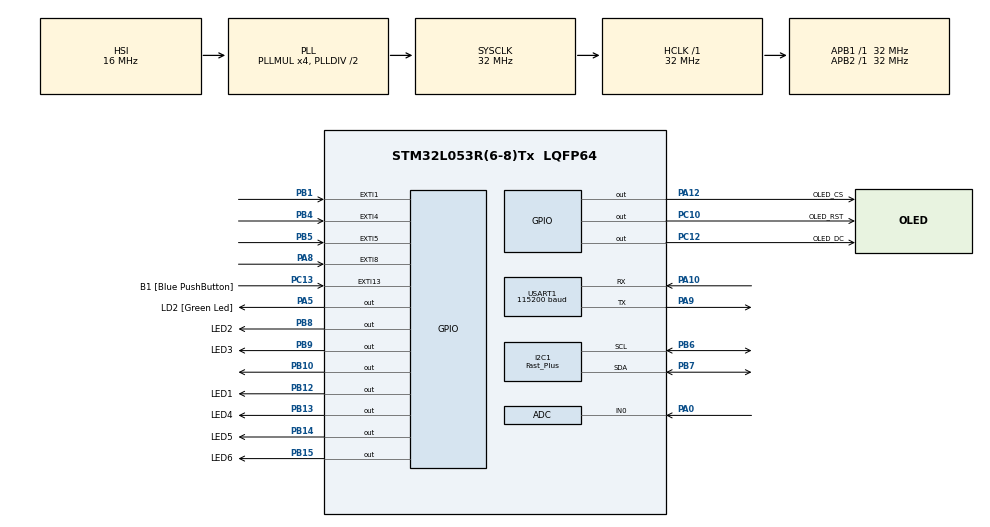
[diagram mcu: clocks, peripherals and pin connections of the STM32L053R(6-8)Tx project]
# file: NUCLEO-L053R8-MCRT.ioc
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ADC.ContinuousConvMode=DISABLE
ADC.DMAContinuousRequests=DISABLE
I2C1.I2C_Speed_Mode=I2C_Fast_Plus
I2C1.Timing=0x00100413
Mcu.Family=STM32L0
Mcu.Name=STM32L053R(6-8)Tx
Mcu.Package=LQFP64
NVIC.EXTI0_1_IRQn=true\:0\:0\:false\:false\:true\:true\:true
NVIC.EXTI4_15_IRQn=true\:0\:0\:false\:false\:true\:true\:true
NVIC.TIM2_IRQn=true\:0\:0\:false\:false\:true\:true\:true
NVIC.TIM6_DAC_IRQn=true\:0\:0\:false\:false\:true\:true\:true
NVIC.USART1_IRQn=true\:0\:0\:false\:false\:true\:true\:true
PA0.Mode=IN0
PA0.Signal=ADC_IN0
PA10.Mode=Asynchronous
PA10.Signal=USART1_RX
PA12.GPIO_Label=OLED_CS
PA12.Signal=GPIO_Output
PA13.GPIO_Label=TMS
PA13.Mode=Serial_Wire
PA13.Signal=SYS_SWDIO
PA14.GPIO_Label=TCK
PA14.Mode=Serial_Wire
PA14.Signal=SYS_SWCLK
PA2.GPIO_Label=USART_TX
PA2.Signal=USART2_TX
PA3.GPIO_Label=USART_RX
PA3.Signal=USART2_RX
PA5.GPIO_Label=LD2 [Green Led]
PA5.Signal=GPIO_Output
PA8.GPIO_ModeDefaultEXTI=GPIO_MODE_IT_RISING_FALLING
PA8.Signal=GPXTI8
PA9.Mode=Asynchronous
PA9.Signal=USART1_TX
PB1.Signal=GPXTI1
PB10.Signal=GPIO_Output
PB12.GPIO_Label=LED1
PB12.Signal=GPIO_Output
PB13.GPIO_Label=LED4
PB13.Signal=GPIO_Output
PB14.GPIO_Label=LED5
PB14.Signal=GPIO_Output
PB15.GPIO_Label=LED6
PB15.Signal=GPIO_Output
PB4.Signal=GPXTI4
PB5.Signal=GPXTI5
PB6.Mode=I2C
PB6.Signal=I2C1_SCL
PB7.Mode=I2C
PB7.Signal=I2C1_SDA
PB8.GPIO_Label=LED2
PB8.Signal=GPIO_Output
PB9.GPIO_Label=LED3
PB9.Signal=GPIO_Output
PC10.GPIO_Label=OLED_RST
PC10.Signal=GPIO_Output
PC12.GPIO_Label=OLED_DC
PC12.Signal=GPIO_Output
PC13.GPIO_Label=B1 [Blue PushButton]
PC13.GPIO_ModeDefaultEXTI=GPIO_MODE_IT_FALLING
PC13.Signal=GPXTI13
PC14-OSC32_IN.Mode=LSE-External-Oscillator
PC14-OSC32_IN.Signal=RCC_OSC32_IN
PC15-OSC32_OUT.Mode=LSE-External-Oscillator
PC15-OSC32_OUT.Signal=RCC_OSC32_OUT
PH0-OSC_IN.Mode=HSE-External-Clock-Source
PH0-OSC_IN.Signal=RCC_OSC_IN
PH1-OSC_OUT.Signal=RCC_OSC_OUT
ProjectManager.HeapSize=0x200
ProjectManager.StackSize=0x400
ProjectManager.TargetToolchain=STM32CubeIDE
RCC.AHBFreq_Value=32000000
RCC.APB1Freq_Value=32000000
RCC.APB1TimFreq_Value=32000000
RCC.APB2Freq_Value=32000000
RCC.APB2TimFreq_Value=32000000
RCC.HCLKFreq_Value=32000000
RCC.HSE_VALUE=8000000
RCC.HSI16_VALUE=16000000
RCC.HSI48_VALUE=48000000
RCC.HSI_VALUE=16000000
RCC.MSI_VALUE=2097000
RCC.PLLMUL=RCC_PLLMUL_4
RCC.SYSCLKFreq_VALUE=32000000
RCC.SYSCLKSource=RCC_SYSCLKSOURCE_PLLCLK
RCC.VCOOutputFreq_Value=64000000
TIM2.Period=32000
TIM6.Period=10000
USART1.BaudRate=115200
USART1.VirtualMode-Asynchronous=VM_ASYNC
VP_TIM2_VS_ClockSourceINT.Mode=Internal
VP_TIM6_VS_ClockSourceINT.Mode=Enable_Timer
board=NUCLEO-L053R8

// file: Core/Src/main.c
/* USER CODE BEGIN Header */
/**
  ******************************************************************************
  * @file           : main.c
  * @brief          : Main program body
  ******************************************************************************
  * @attention
  *
  * <h2><center>&copy; Copyright (c) 2021 STMicroelectronics.
  * All rights reserved.</center></h2>
  *
  * This software component is licensed by ST under BSD 3-Clause license,
  * the "License"; You may not use this file except in compliance with the
  * License. You may obtain a copy of the License at:
  *                        opensource.org/licenses/BSD-3-Clause
  *
  ******************************************************************************
  */
/* USER CODE END Header */
#include "main.h"

/* USER CODE BEGIN Includes */
#include "adaptor.h"
#include "MCRuntime_V1.h"
/* USER CODE END Includes */

ADC_HandleTypeDef hadc;

I2C_HandleTypeDef hi2c1;

TIM_HandleTypeDef htim2;
TIM_HandleTypeDef htim6;

UART_HandleTypeDef huart1;

void SystemClock_Config(void);
static void MX_GPIO_Init(void);
static void MX_USART1_UART_Init(void);
static void MX_TIM6_Init(void);
static void MX_I2C1_Init(void);
static void MX_ADC_Init(void);
static void MX_TIM2_Init(void);

int main(void)
{

  /* MCU Configuration--------------------------------------------------------*/

  /* Reset of all peripherals, Initializes the Flash interface and the Systick. */
  HAL_Init();

  /* Configure the system clock */
  SystemClock_Config();

  /* Initialize all configured peripherals */
  MX_GPIO_Init();
  MX_USART1_UART_Init();
  MX_TIM6_Init();
  MX_I2C1_Init();
  MX_ADC_Init();
  MX_TIM2_Init();
  /* USER CODE BEGIN 2 */

  //User function registers
  //register_user_callback_func(MODBUS_UART_CALLBACK_FUNCTION_SLOT, userUartFunc);

  init_comm_data_service();
  init_comm_timing_service();
  initiate_input_channels();
  initiate_output_channels();
  /* USER CODE END 2 */

  /* Infinite loop */
  while (1)
  {
	  mcCore_SM();
  }
}

void SystemClock_Config(void)
{
  RCC_OscInitTypeDef RCC_OscInitStruct = {0};
  RCC_ClkInitTypeDef RCC_ClkInitStruct = {0};
  RCC_PeriphCLKInitTypeDef PeriphClkInit = {0};

  /** Configure the main internal regulator output voltage
  */
  __HAL_PWR_VOLTAGESCALING_CONFIG(PWR_REGULATOR_VOLTAGE_SCALE1);
  /** Initializes the RCC Oscillators according to the specified parameters
  * in the RCC_OscInitTypeDef structure.
  */
  RCC_OscInitStruct.OscillatorType = RCC_OSCILLATORTYPE_HSI;
  RCC_OscInitStruct.HSIState = RCC_HSI_ON;
  RCC_OscInitStruct.HSICalibrationValue = RCC_HSICALIBRATION_DEFAULT;
  RCC_OscInitStruct.PLL.PLLState = RCC_PLL_ON;
  RCC_OscInitStruct.PLL.PLLSource = RCC_PLLSOURCE_HSI;
  RCC_OscInitStruct.PLL.PLLMUL = RCC_PLLMUL_4;
  RCC_OscInitStruct.PLL.PLLDIV = RCC_PLLDIV_2;
  if (HAL_RCC_OscConfig(&RCC_OscInitStruct) != HAL_OK)
  {
    Error_Handler();
  }
  /** Initializes the CPU, AHB and APB buses clocks
  */
  RCC_ClkInitStruct.ClockType = RCC_CLOCKTYPE_HCLK|RCC_CLOCKTYPE_SYSCLK
                              |RCC_CLOCKTYPE_PCLK1|RCC_CLOCKTYPE_PCLK2;
  RCC_ClkInitStruct.SYSCLKSource = RCC_SYSCLKSOURCE_PLLCLK;
  RCC_ClkInitStruct.AHBCLKDivider = RCC_SYSCLK_DIV1;
  RCC_ClkInitStruct.APB1CLKDivider = RCC_HCLK_DIV1;
  RCC_ClkInitStruct.APB2CLKDivider = RCC_HCLK_DIV1;

  if (HAL_RCC_ClockConfig(&RCC_ClkInitStruct, FLASH_LATENCY_1) != HAL_OK)
  {
    Error_Handler();
  }
  PeriphClkInit.PeriphClockSelection = RCC_PERIPHCLK_USART1|RCC_PERIPHCLK_I2C1;
  PeriphClkInit.Usart1ClockSelection = RCC_USART1CLKSOURCE_PCLK2;
  PeriphClkInit.I2c1ClockSelection = RCC_I2C1CLKSOURCE_PCLK1;
  if (HAL_RCCEx_PeriphCLKConfig(&PeriphClkInit) != HAL_OK)
  {
    Error_Handler();
  }
}

static void MX_ADC_Init(void)
{

  ADC_ChannelConfTypeDef sConfig = {0};

  /** Configure the global features of the ADC (Clock, Resolution, Data Alignment and number of conversion)
  */
  hadc.Instance = ADC1;
  hadc.Init.OversamplingMode = DISABLE;
  hadc.Init.ClockPrescaler = ADC_CLOCK_SYNC_PCLK_DIV2;
  hadc.Init.Resolution = ADC_RESOLUTION_12B;
  hadc.Init.SamplingTime = ADC_SAMPLETIME_1CYCLE_5;
  hadc.Init.ScanConvMode = ADC_SCAN_DIRECTION_FORWARD;
  hadc.Init.DataAlign = ADC_DATAALIGN_RIGHT;
  hadc.Init.ContinuousConvMode = DISABLE;
  hadc.Init.DiscontinuousConvMode = DISABLE;
  hadc.Init.ExternalTrigConvEdge = ADC_EXTERNALTRIGCONVEDGE_NONE;
  hadc.Init.ExternalTrigConv = ADC_SOFTWARE_START;
  hadc.Init.DMAContinuousRequests = DISABLE;
  hadc.Init.EOCSelection = ADC_EOC_SINGLE_CONV;
  hadc.Init.Overrun = ADC_OVR_DATA_PRESERVED;
  hadc.Init.LowPowerAutoWait = DISABLE;
  hadc.Init.LowPowerFrequencyMode = DISABLE;
  hadc.Init.LowPowerAutoPowerOff = DISABLE;
  if (HAL_ADC_Init(&hadc) != HAL_OK)
  {
    Error_Handler();
  }
  /** Configure for the selected ADC regular channel to be converted.
  */
  sConfig.Channel = ADC_CHANNEL_0;
  sConfig.Rank = ADC_RANK_CHANNEL_NUMBER;
  if (HAL_ADC_ConfigChannel(&hadc, &sConfig) != HAL_OK)
  {
    Error_Handler();
  }

}

static void MX_I2C1_Init(void)
{

  hi2c1.Instance = I2C1;
  hi2c1.Init.Timing = 0x00100413;
  hi2c1.Init.OwnAddress1 = 0;
  hi2c1.Init.AddressingMode = I2C_ADDRESSINGMODE_7BIT;
  hi2c1.Init.DualAddressMode = I2C_DUALADDRESS_DISABLE;
  hi2c1.Init.OwnAddress2 = 0;
  hi2c1.Init.OwnAddress2Masks = I2C_OA2_NOMASK;
  hi2c1.Init.GeneralCallMode = I2C_GENERALCALL_DISABLE;
  hi2c1.Init.NoStretchMode = I2C_NOSTRETCH_DISABLE;
  if (HAL_I2C_Init(&hi2c1) != HAL_OK)
  {
    Error_Handler();
  }
  /** Configure Analogue filter
  */
  if (HAL_I2CEx_ConfigAnalogFilter(&hi2c1, I2C_ANALOGFILTER_ENABLE) != HAL_OK)
  {
    Error_Handler();
  }
  /** Configure Digital filter
  */
  if (HAL_I2CEx_ConfigDigitalFilter(&hi2c1, 0) != HAL_OK)
  {
    Error_Handler();
  }
  /** I2C Fast mode Plus enable
  */
  HAL_I2CEx_EnableFastModePlus(I2C_FASTMODEPLUS_I2C1);

}

static void MX_TIM2_Init(void)
{

  TIM_ClockConfigTypeDef sClockSourceConfig = {0};
  TIM_MasterConfigTypeDef sMasterConfig = {0};

  htim2.Instance = TIM2;
  htim2.Init.Prescaler = 0;
  htim2.Init.CounterMode = TIM_COUNTERMODE_UP;
  htim2.Init.Period = 32000;
  htim2.Init.ClockDivision = TIM_CLOCKDIVISION_DIV1;
  htim2.Init.AutoReloadPreload = TIM_AUTORELOAD_PRELOAD_DISABLE;
  if (HAL_TIM_Base_Init(&htim2) != HAL_OK)
  {
    Error_Handler();
  }
  sClockSourceConfig.ClockSource = TIM_CLOCKSOURCE_INTERNAL;
  if (HAL_TIM_ConfigClockSource(&htim2, &sClockSourceConfig) != HAL_OK)
  {
    Error_Handler();
  }
  sMasterConfig.MasterOutputTrigger = TIM_TRGO_RESET;
  sMasterConfig.MasterSlaveMode = TIM_MASTERSLAVEMODE_DISABLE;
  if (HAL_TIMEx_MasterConfigSynchronization(&htim2, &sMasterConfig) != HAL_OK)
  {
    Error_Handler();
  }

}

static void MX_TIM6_Init(void)
{

  TIM_MasterConfigTypeDef sMasterConfig = {0};

  htim6.Instance = TIM6;
  htim6.Init.Prescaler = 0;
  htim6.Init.CounterMode = TIM_COUNTERMODE_UP;
  htim6.Init.Period = 10000;
  htim6.Init.AutoReloadPreload = TIM_AUTORELOAD_PRELOAD_DISABLE;
  if (HAL_TIM_Base_Init(&htim6) != HAL_OK)
  {
    Error_Handler();
  }
  sMasterConfig.MasterOutputTrigger = TIM_TRGO_RESET;
  sMasterConfig.MasterSlaveMode = TIM_MASTERSLAVEMODE_DISABLE;
  if (HAL_TIMEx_MasterConfigSynchronization(&htim6, &sMasterConfig) != HAL_OK)
  {
    Error_Handler();
  }

}

static void MX_USART1_UART_Init(void)
{

  huart1.Instance = USART1;
  huart1.Init.BaudRate = 115200;
  huart1.Init.WordLength = UART_WORDLENGTH_8B;
  huart1.Init.StopBits = UART_STOPBITS_1;
  huart1.Init.Parity = UART_PARITY_NONE;
  huart1.Init.Mode = UART_MODE_TX_RX;
  huart1.Init.HwFlowCtl = UART_HWCONTROL_NONE;
  huart1.Init.OverSampling = UART_OVERSAMPLING_16;
  huart1.Init.OneBitSampling = UART_ONE_BIT_SAMPLE_DISABLE;
  huart1.AdvancedInit.AdvFeatureInit = UART_ADVFEATURE_NO_INIT;
  if (HAL_UART_Init(&huart1) != HAL_OK)
  {
    Error_Handler();
  }

}

static void MX_GPIO_Init(void)
{
  GPIO_InitTypeDef GPIO_InitStruct = {0};

  /* GPIO Ports Clock Enable */
  __HAL_RCC_GPIOC_CLK_ENABLE();
  __HAL_RCC_GPIOH_CLK_ENABLE();
  __HAL_RCC_GPIOA_CLK_ENABLE();
  __HAL_RCC_GPIOB_CLK_ENABLE();

  /*Configure GPIO pin Output Level */
  HAL_GPIO_WritePin(GPIOA, LD2_Pin|OLED_CS_Pin, GPIO_PIN_RESET);

  /*Configure GPIO pin Output Level */
  HAL_GPIO_WritePin(GPIOB, GPIO_PIN_10|LED1_Pin|LED4_Pin|LED5_Pin
                          |LED6_Pin|LED2_Pin|LED3_Pin, GPIO_PIN_RESET);

  /*Configure GPIO pin Output Level */
  HAL_GPIO_WritePin(GPIOC, OLED_RST_Pin|OLED_DC_Pin, GPIO_PIN_RESET);

  /*Configure GPIO pin : B1_Pin */
  GPIO_InitStruct.Pin = B1_Pin;
  GPIO_InitStruct.Mode = GPIO_MODE_IT_FALLING;
  GPIO_InitStruct.Pull = GPIO_NOPULL;
  HAL_GPIO_Init(B1_GPIO_Port, &GPIO_InitStruct);

  /*Configure GPIO pins : USART_TX_Pin USART_RX_Pin */
  GPIO_InitStruct.Pin = USART_TX_Pin|USART_RX_Pin;
  GPIO_InitStruct.Mode = GPIO_MODE_AF_PP;
  GPIO_InitStruct.Pull = GPIO_NOPULL;
  GPIO_InitStruct.Speed = GPIO_SPEED_FREQ_VERY_HIGH;
  GPIO_InitStruct.Alternate = GPIO_AF4_USART2;
  HAL_GPIO_Init(GPIOA, &GPIO_InitStruct);

  /*Configure GPIO pins : LD2_Pin OLED_CS_Pin */
  GPIO_InitStruct.Pin = LD2_Pin|OLED_CS_Pin;
  GPIO_InitStruct.Mode = GPIO_MODE_OUTPUT_PP;
  GPIO_InitStruct.Pull = GPIO_NOPULL;
  GPIO_InitStruct.Speed = GPIO_SPEED_FREQ_LOW;
  HAL_GPIO_Init(GPIOA, &GPIO_InitStruct);

  /*Configure GPIO pins : PB1 PB4 PB5 */
  GPIO_InitStruct.Pin = GPIO_PIN_1|GPIO_PIN_4|GPIO_PIN_5;
  GPIO_InitStruct.Mode = GPIO_MODE_IT_RISING;
  GPIO_InitStruct.Pull = GPIO_NOPULL;
  HAL_GPIO_Init(GPIOB, &GPIO_InitStruct);

  /*Configure GPIO pins : PB10 LED1_Pin LED4_Pin LED5_Pin
                           LED6_Pin LED2_Pin LED3_Pin */
  GPIO_InitStruct.Pin = GPIO_PIN_10|LED1_Pin|LED4_Pin|LED5_Pin
                          |LED6_Pin|LED2_Pin|LED3_Pin;
  GPIO_InitStruct.Mode = GPIO_MODE_OUTPUT_PP;
  GPIO_InitStruct.Pull = GPIO_NOPULL;
  GPIO_InitStruct.Speed = GPIO_SPEED_FREQ_LOW;
  HAL_GPIO_Init(GPIOB, &GPIO_InitStruct);

  /*Configure GPIO pin : PA8 */
  GPIO_InitStruct.Pin = GPIO_PIN_8;
  GPIO_InitStruct.Mode = GPIO_MODE_IT_RISING_FALLING;
  GPIO_InitStruct.Pull = GPIO_NOPULL;
  HAL_GPIO_Init(GPIOA, &GPIO_InitStruct);

  /*Configure GPIO pins : OLED_RST_Pin OLED_DC_Pin */
  GPIO_InitStruct.Pin = OLED_RST_Pin|OLED_DC_Pin;
  GPIO_InitStruct.Mode = GPIO_MODE_OUTPUT_PP;
  GPIO_InitStruct.Pull = GPIO_NOPULL;
  GPIO_InitStruct.Speed = GPIO_SPEED_FREQ_LOW;
  HAL_GPIO_Init(GPIOC, &GPIO_InitStruct);

  /* EXTI interrupt init*/
  HAL_NVIC_SetPriority(EXTI0_1_IRQn, 0, 0);
  HAL_NVIC_EnableIRQ(EXTI0_1_IRQn);

  HAL_NVIC_SetPriority(EXTI4_15_IRQn, 0, 0);
  HAL_NVIC_EnableIRQ(EXTI4_15_IRQn);

}

void Error_Handler(void)
{
  __disable_irq();
  while (1)
  {
  }
}

/************************ (C) COPYRIGHT STMicroelectronics *****END OF FILE****/
